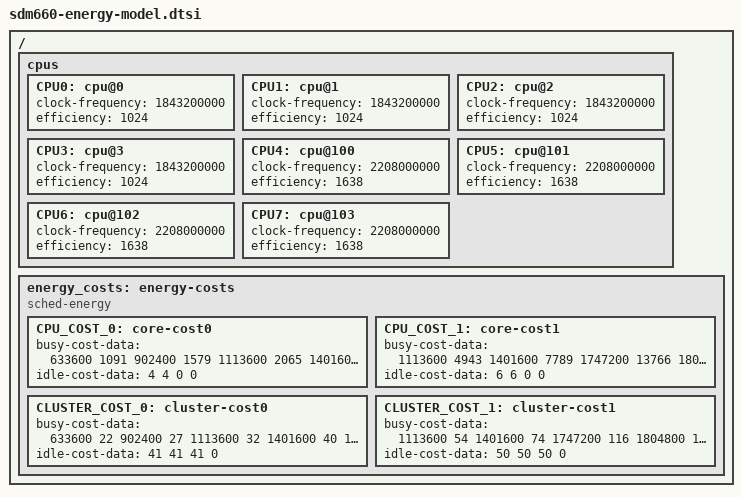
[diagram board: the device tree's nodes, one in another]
// SPDX-License-Identifier: GPL-2.0

/ {
	cpus {
		CPU0: cpu@0 {
			clock-frequency = <1843200000>;
			efficiency = <1024>;
			#cooling-cells = <2>;
			};

		CPU1: cpu@1 {
			clock-frequency = <1843200000>;
			efficiency = <1024>;
			#cooling-cells = <2>;
			};

		CPU2: cpu@2 {
			clock-frequency = <1843200000>;
			efficiency = <1024>;
			#cooling-cells = <2>;
			};

		CPU3: cpu@3 {	
			clock-frequency = <1843200000>;
			efficiency = <1024>;
			#cooling-cells = <2>;
			};

		CPU4: cpu@100 {
			clock-frequency = <2208000000>;
			efficiency = <1638>;
			#cooling-cells = <2>;
			};

		CPU5: cpu@101 {
			clock-frequency = <2208000000>;
			efficiency = <1638>;
			#cooling-cells = <2>;
			};

		CPU6: cpu@102 {
			clock-frequency = <2208000000>;
			efficiency = <1638>;
			#cooling-cells = <2>;
			};

		CPU7: cpu@103 {
			clock-frequency = <2208000000>;
			efficiency = <1638>;
			#cooling-cells = <2>;
			};
	};

	energy_costs: energy-costs {
		compatible = "sched-energy";

		CPU_COST_0: core-cost0 {
			busy-cost-data = <
				 633600 1091
				 902400 1579
				1113600 2065
				1401600 3034
				1536000 3686
				1747200 5105
				1843200 5959
			>;
			idle-cost-data = <
				4 4 0 0
			>;
		};

		CPU_COST_1: core-cost1 {
			busy-cost-data = <
				1113600 4943
				1401600 7789
				1747200 13766
				1804800 15181
				1958400 19758
				2150400 27509
				2208000 30369
			>;
			idle-cost-data = <
			        6 6 0 0
			>;
		};

		CLUSTER_COST_0: cluster-cost0 {
			busy-cost-data = <
				 633600 22
				 902400 27
				1113600 32
				1401600 40
				1536000 45
				1747200 55
				1843200 61
			>;
			idle-cost-data = <
				 41 41 41 0
			>;
		};

		CLUSTER_COST_1: cluster-cost1 {
			busy-cost-data = <
				1113600 54
				1401600 74
				1747200 116
				1804800 125
				1958400 157
				2150400 209
				2208000 229
			>;
			idle-cost-data = <
				50 50 50 0
			>;
		};
	};
};		
